# CM_DEVICE register map
Vendor: Texas Instruments
Peripheral module from a debugger description file (folder am437x).
Registers are 32-bit, access per field, no defined reset value unless marked. A register's access mark holds for its fields unless they carry their own. Offsets are as the file gives them; lines under a group give offsets from that group; [hi:lo] are bit positions; {n}, {i} and the like mark numbered series; 'fields as' and 'values as' point back to an identical list; <NAME> marks a mode.

## CM_DEVICE
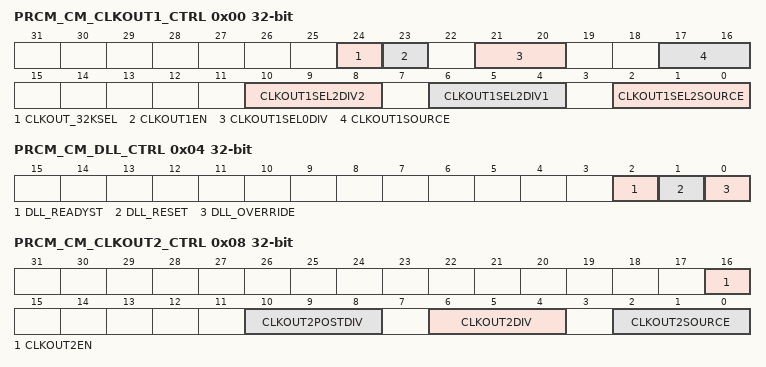
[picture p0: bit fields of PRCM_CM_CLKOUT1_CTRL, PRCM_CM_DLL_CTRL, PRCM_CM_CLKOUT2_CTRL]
0x00 PRCM_CM_CLKOUT1_CTRL — This register provides the control over CLKOUT1 output
  [24] CLKOUT_32KSEL rw — This bit controls the 32KHz clock source selection for CLKOUT1 and CLKOUT2 output clocks
    1=en_2_0x1 (Select 32KHz clock source.); 0=en_1_0x0 (Selects 32KHz clock source.)
  [23] CLKOUT1EN rw — This bit controls the external clock CLKOUT1 activity
    1=en_2_0x1 (SYS_CLKOUT1 is enabled); 0=en_1_0x0 (SYS_CLKOUT1 is disabled)
  [21:20] CLKOUT1SEL0DIV rw — This field controls the external clock CLKOUT1 divison factor, when CLKOUT1SOURCE=SEL0
    {v}=en_{v+1}_{0x0+v} (Divide CLKOUT1 by {v+1}) (v=0..3)
  [17:16] CLKOUT1SOURCE rw — This field selects the external output CLKOUT1 clock source
    3=en_4_0x3 (Selects clock from DPLL_EXTDEV); 2=en_3_0x2 (Selects clk based on CLKOUT1SEL2SOURCE, CLKOUT1SEL2DIV1 and CLKOUT1SEL2DIV2); 1=en_2_0x1 (Select 32KHz clock source.); 0=en_1_0x0 (Selects 32KHz clock source.)
  [10:8] CLKOUT1SEL2DIV2 rw — This field controls the external clock CLKOUT1 first divison factor, when CLKOUT1SOURCE=SEL2
    7=en_8_0x7 (Reserved); 6=en_7_0x6 (Reserved); 5=en_6_0x5 (Divide clock further by 32); 4=en_5_0x4 (Divide clock further by 16); 3=en_4_0x3 (Divide clock further by 8); 2=en_3_0x2 (Divide clock further by 4); 1=en_2_0x1 (Divide clock further by 2); 0=en_1_0x0 (Divide clock further by 1)
  [6:4] CLKOUT1SEL2DIV1 rw — This field controls the external clock CLKOUT1 first divison factor, when CLKOUT1SOURCE=SEL2
    {v}=en_{v+1}_{0x0+v} (SYS_CLKOUT2/{v+1}) (v=0..7)
  [2:0] CLKOUT1SEL2SOURCE rw — This field selects the CLKOUT1, when CLKOUT1SOURCE=SEL2,
    5=en_6_0x5 (Selects MPU_PLL_CLKOUT); 4=en_5_0x4 (Selects LCD Pixel Clock[PIXEL_CLK]); 3=en_4_0x3 (Selects192Mhz clock from PER PLL[PER_CLKOUT_M2]); 2=en_3_0x2 (Selects DDR_PHY_Clk); 1=en_2_0x1 (Select 32KHz clock source.); 0=en_1_0x0 (Selects 32KHz clock source.)
0x04 PRCM_CM_DLL_CTRL — Special register for DLL control
  [2] DLL_READYST ro — Gives the DLL ready status. [[br]] It is the AND of individual DLL_READY signals.
    1=en_2_0x1 (1); 0=en_1_0x0 (0)
  [1] DLL_RESET rw — Controls DLL Reset. [[br]] Applicable only for DVFS. [[br]] This reset is to be used only during DVFS when DLL frequency is being changed
    1=en_2_0x1 (Reset DLL); 0=en_1_0x0 (No Reset to DLL)
  [0] DLL_OVERRIDE rw — Control if DLL lock and code outputs are overriden or not
    1=en_2_0x1 (Lock output is overriden to '1' and code output is overriden with a value coming from control module.); 0=en_1_0x0 (Lock and code outputs are not overriden)
0x08 PRCM_CM_CLKOUT2_CTRL — This register provides the control over CLKOUT2 output
  [16] CLKOUT2EN rw — This bit controls the external clock activity
    1=en_2_0x1 (SYS_CLKOUT2 is enabled); 0=en_1_0x0 (SYS_CLKOUT2 is disabled)
  [10:8] CLKOUT2POSTDIV rw — THis field controls the external clock CLKOUT2 post divison factor. [[br]] This division factor will divide the clock coming out of divide controlled by CLKOUT2DIV bit-field
    values as PRCM_CM_CLKOUT1_CTRL.CLKOUT1SEL2DIV2
  [6:4] CLKOUT2DIV rw — THis field controls the external clock CLKOUT2 divison factor
    {v}=en_{v+1}_{0x0+v} (SYS_CLKOUT2/{v+1}) (v=0..7)
  [2:0] CLKOUT2SOURCE rw — This field selects the external output CLKOUT2 clock source
    6=en_7_0x6 (Selects DPLL_EXTDEV clkout); 5=en_6_0x5 (Selects MPU_PLL_CLKOUT); 4=en_5_0x4 (Selects LCD Pixel Clock[PIXEL_CLK]); 3=en_4_0x3 (Selects192Mhz clock from PER PLL[PER_CLKOUT_M2]); 2=en_3_0x2 (Selects DDR_PHY_Clk); 1=en_2_0x1 (Selects L3F_CLK Clock); 0=en_1_0x0 (Selects 32KHz clock source)
